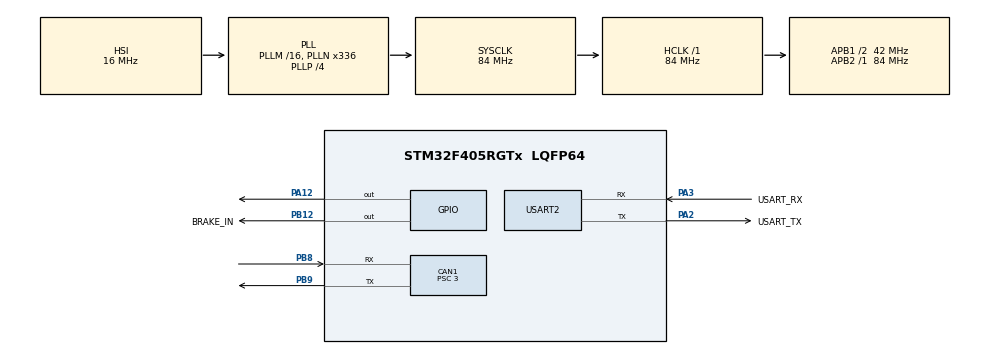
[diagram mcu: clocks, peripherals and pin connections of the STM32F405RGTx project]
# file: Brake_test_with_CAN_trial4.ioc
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CAN1.BS1=CAN_BS1_11TQ
CAN1.BS2=CAN_BS2_2TQ
CAN1.CalculateBaudRate=1000000
CAN1.CalculateTimeBit=1000
CAN1.CalculateTimeQuantum=71.42857142857143
CAN1.NART=ENABLE
CAN1.Prescaler=3
Mcu.Family=STM32F4
Mcu.Name=STM32F405RGTx
Mcu.Package=LQFP64
NVIC.CAN1_RX0_IRQn=true\:0\:0\:false\:false\:true\:true\:true\:true
NVIC.CAN1_RX1_IRQn=true\:0\:0\:false\:false\:true\:true\:true\:true
NVIC.CAN1_SCE_IRQn=true\:0\:0\:false\:false\:true\:true\:true\:true
NVIC.CAN1_TX_IRQn=true\:0\:0\:false\:false\:true\:true\:true\:true
NVIC.PriorityGroup=NVIC_PRIORITYGROUP_4
PA12.Signal=GPIO_Output
PA13.GPIO_Label=TMS
PA13.Mode=Serial_Wire
PA13.Signal=SYS_JTMS-SWDIO
PA14.GPIO_Label=TCK
PA14.Mode=Serial_Wire
PA14.Signal=SYS_JTCK-SWCLK
PA2.GPIO_Label=USART_TX
PA2.Mode=Asynchronous
PA2.Signal=USART2_TX
PA3.GPIO_Label=USART_RX
PA3.Mode=Asynchronous
PA3.Signal=USART2_RX
PB12.GPIO_Label=BRAKE_IN
PB12.Signal=GPIO_Output
PB8.Mode=CAN_Activate
PB8.Signal=CAN1_RX
PB9.Mode=CAN_Activate
PB9.Signal=CAN1_TX
PC14-OSC32_IN.Mode=LSE-External-Oscillator
PC14-OSC32_IN.Signal=RCC_OSC32_IN
PC15-OSC32_OUT.Mode=LSE-External-Oscillator
PC15-OSC32_OUT.Signal=RCC_OSC32_OUT
PH0-OSC_IN.Mode=HSE-External-Oscillator
PH0-OSC_IN.Signal=RCC_OSC_IN
PH1-OSC_OUT.Mode=HSE-External-Oscillator
PH1-OSC_OUT.Signal=RCC_OSC_OUT
ProjectManager.HeapSize=0x200
ProjectManager.StackSize=0x400
ProjectManager.TargetToolchain=STM32CubeIDE
RCC.48MHZClocksFreq_Value=84000000
RCC.AHBFreq_Value=84000000
RCC.APB1CLKDivider=RCC_HCLK_DIV2
RCC.APB1Freq_Value=42000000
RCC.APB1TimFreq_Value=84000000
RCC.APB2Freq_Value=84000000
RCC.APB2TimFreq_Value=84000000
RCC.CortexFreq_Value=84000000
RCC.HCLKFreq_Value=84000000
RCC.HSE_VALUE=12000000
RCC.HSI_VALUE=16000000
RCC.PLLN=336
RCC.PLLP=RCC_PLLP_DIV4
RCC.SYSCLKFreq_VALUE=84000000
RCC.SYSCLKSource=RCC_SYSCLKSOURCE_PLLCLK
RCC.VCOOutputFreq_Value=336000000
TIM14.Prescaler=41
USART2.VirtualMode=VM_ASYNC
VP_TIM14_VS_ClockSourceINT.Mode=Enable_Timer
board=custom

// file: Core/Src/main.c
/* USER CODE BEGIN Header */
/**
  ******************************************************************************
  * @file           : main.c
  * @brief          : Main program body
  ******************************************************************************
  * @attention
  *
  * Copyright (c) 2026 STMicroelectronics.
  * All rights reserved.
  *
  * This software is licensed under terms that can be found in the LICENSE file
  * in the root directory of this software component.
  * If no LICENSE file comes with this software, it is provided AS-IS.
  *
  ******************************************************************************
  */
/* USER CODE END Header */
#include "main.h"

/* USER CODE BEGIN Includes */
#include "CO_app_STM32.h"
#include "cia402.h"
/* USER CODE END Includes */

CAN_HandleTypeDef hcan1;

TIM_HandleTypeDef htim14;

UART_HandleTypeDef huart2;

void SystemClock_Config(void);
static void MX_GPIO_Init(void);
static void MX_CAN1_Init(void);
static void MX_TIM14_Init(void);
static void MX_USART2_UART_Init(void);

int main(void)
{

  /* MCU Configuration--------------------------------------------------------*/

  /* Reset of all peripherals, Initializes the Flash interface and the Systick. */
  HAL_Init();

  /* Configure the system clock */
  SystemClock_Config();

  /* Initialize all configured peripherals */
  MX_GPIO_Init();
  MX_CAN1_Init();
  MX_TIM14_Init();
  MX_USART2_UART_Init();
  /* USER CODE BEGIN 2 */

  CANopenNodeSTM32 canOpenNodeSTM32;
  canOpenNodeSTM32.CANHandle = &hcan1;
  canOpenNodeSTM32.HWInitFunction = MX_CAN1_Init;
  canOpenNodeSTM32.timerHandle = &htim14;
  canOpenNodeSTM32.desiredNodeID = 40;
  canOpenNodeSTM32.baudrate = 1000;
  canopen_app_init(&canOpenNodeSTM32);

  /* Initialize CiA402 state machine */
  CIA402_Init();

  /* USER CODE END 2 */

  /* Infinite loop */
  /* USER CODE BEGIN WHILE */
  while (1)
  {
      canopen_app_process();
      CIA402_Process();

      if(OD_RAM.x311F_PA5 != 0)
      {
          HAL_GPIO_WritePin(GPIOA, GPIO_PIN_12, GPIO_PIN_SET);    // LED ON
          HAL_GPIO_WritePin(BRAKE_IN_GPIO_Port, BRAKE_IN_Pin, GPIO_PIN_SET);   // BRAKE ON
      }
      else
      {
          HAL_GPIO_WritePin(GPIOA, GPIO_PIN_12, GPIO_PIN_RESET);  // LED OFF
          HAL_GPIO_WritePin(BRAKE_IN_GPIO_Port, BRAKE_IN_Pin, GPIO_PIN_RESET); // BRAKE OFF
      }
  }
  /* USER CODE END 3 */
}

void SystemClock_Config(void)
{
  RCC_OscInitTypeDef RCC_OscInitStruct = {0};
  RCC_ClkInitTypeDef RCC_ClkInitStruct = {0};

  /** Configure the main internal regulator output voltage
  */
  __HAL_RCC_PWR_CLK_ENABLE();
  __HAL_PWR_VOLTAGESCALING_CONFIG(PWR_REGULATOR_VOLTAGE_SCALE1);

  /** Initializes the RCC Oscillators according to the specified parameters
  * in the RCC_OscInitTypeDef structure.
  */
  RCC_OscInitStruct.OscillatorType = RCC_OSCILLATORTYPE_HSI;
  RCC_OscInitStruct.HSIState = RCC_HSI_ON;
  RCC_OscInitStruct.HSICalibrationValue = RCC_HSICALIBRATION_DEFAULT;
  RCC_OscInitStruct.PLL.PLLState = RCC_PLL_ON;
  RCC_OscInitStruct.PLL.PLLSource = RCC_PLLSOURCE_HSI;
  RCC_OscInitStruct.PLL.PLLM = 16;
  RCC_OscInitStruct.PLL.PLLN = 336;
  RCC_OscInitStruct.PLL.PLLP = RCC_PLLP_DIV4;
  RCC_OscInitStruct.PLL.PLLQ = 4;
  if (HAL_RCC_OscConfig(&RCC_OscInitStruct) != HAL_OK)
  {
    Error_Handler();
  }

  /** Initializes the CPU, AHB and APB buses clocks
  */
  RCC_ClkInitStruct.ClockType = RCC_CLOCKTYPE_HCLK|RCC_CLOCKTYPE_SYSCLK
                              |RCC_CLOCKTYPE_PCLK1|RCC_CLOCKTYPE_PCLK2;
  RCC_ClkInitStruct.SYSCLKSource = RCC_SYSCLKSOURCE_PLLCLK;
  RCC_ClkInitStruct.AHBCLKDivider = RCC_SYSCLK_DIV1;
  RCC_ClkInitStruct.APB1CLKDivider = RCC_HCLK_DIV2;
  RCC_ClkInitStruct.APB2CLKDivider = RCC_HCLK_DIV1;

  if (HAL_RCC_ClockConfig(&RCC_ClkInitStruct, FLASH_LATENCY_2) != HAL_OK)
  {
    Error_Handler();
  }
}

static void MX_CAN1_Init(void)
{

  hcan1.Instance = CAN1;
  hcan1.Init.Prescaler = 3;
  hcan1.Init.Mode = CAN_MODE_NORMAL;
  hcan1.Init.SyncJumpWidth = CAN_SJW_1TQ;
  hcan1.Init.TimeSeg1 = CAN_BS1_11TQ;
  hcan1.Init.TimeSeg2 = CAN_BS2_2TQ;
  hcan1.Init.TimeTriggeredMode = DISABLE;
  hcan1.Init.AutoBusOff = DISABLE;
  hcan1.Init.AutoWakeUp = DISABLE;
  hcan1.Init.AutoRetransmission = ENABLE;
  hcan1.Init.ReceiveFifoLocked = DISABLE;
  hcan1.Init.TransmitFifoPriority = DISABLE;
  if (HAL_CAN_Init(&hcan1) != HAL_OK)
  {
    Error_Handler();
  }

}

static void MX_TIM14_Init(void)
{

  htim14.Instance = TIM14;
  htim14.Init.Prescaler = 41;
  htim14.Init.CounterMode = TIM_COUNTERMODE_UP;
  htim14.Init.Period = 1000;
  htim14.Init.ClockDivision = TIM_CLOCKDIVISION_DIV1;
  htim14.Init.AutoReloadPreload = TIM_AUTORELOAD_PRELOAD_DISABLE;
  if (HAL_TIM_Base_Init(&htim14) != HAL_OK)
  {
    Error_Handler();
  }

}

static void MX_USART2_UART_Init(void)
{

  huart2.Instance = USART2;
  huart2.Init.BaudRate = 115200;
  huart2.Init.WordLength = UART_WORDLENGTH_8B;
  huart2.Init.StopBits = UART_STOPBITS_1;
  huart2.Init.Parity = UART_PARITY_NONE;
  huart2.Init.Mode = UART_MODE_TX_RX;
  huart2.Init.HwFlowCtl = UART_HWCONTROL_NONE;
  huart2.Init.OverSampling = UART_OVERSAMPLING_16;
  if (HAL_UART_Init(&huart2) != HAL_OK)
  {
    Error_Handler();
  }

}

static void MX_GPIO_Init(void)
{
  GPIO_InitTypeDef GPIO_InitStruct = {0};

  /* GPIO Ports Clock Enable */
  __HAL_RCC_GPIOC_CLK_ENABLE();
  __HAL_RCC_GPIOH_CLK_ENABLE();
  __HAL_RCC_GPIOA_CLK_ENABLE();
  __HAL_RCC_GPIOB_CLK_ENABLE();

  /*Configure GPIO pin Output Level */
  HAL_GPIO_WritePin(BRAKE_IN_GPIO_Port, BRAKE_IN_Pin, GPIO_PIN_RESET);

  /*Configure GPIO pin Output Level */
  HAL_GPIO_WritePin(GPIOA, GPIO_PIN_12, GPIO_PIN_RESET);

  /*Configure GPIO pin : BRAKE_IN_Pin */
  GPIO_InitStruct.Pin = BRAKE_IN_Pin;
  GPIO_InitStruct.Mode = GPIO_MODE_OUTPUT_PP;
  GPIO_InitStruct.Pull = GPIO_NOPULL;
  GPIO_InitStruct.Speed = GPIO_SPEED_FREQ_LOW;
  HAL_GPIO_Init(BRAKE_IN_GPIO_Port, &GPIO_InitStruct);

  /*Configure GPIO pin : PA12 */
  GPIO_InitStruct.Pin = GPIO_PIN_12;
  GPIO_InitStruct.Mode = GPIO_MODE_OUTPUT_PP;
  GPIO_InitStruct.Pull = GPIO_NOPULL;
  GPIO_InitStruct.Speed = GPIO_SPEED_FREQ_LOW;
  HAL_GPIO_Init(GPIOA, &GPIO_InitStruct);

}

void Error_Handler(void)
{
  __disable_irq();
  while (1)
  {
  }
}
